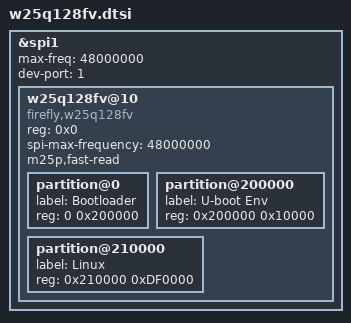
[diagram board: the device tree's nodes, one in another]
&spi1 {
	status = "okay";
	max-freq = <48000000>;
	dev-port = <1>;

	w25q128fv@10{
		status = "okay";
		#address-cells = <1>;
		#size-cells = <1>;
		compatible = "firefly,w25q128fv";
		reg = <0x0>;
		spi-max-frequency = <48000000>;
		m25p,fast-read;

		partition@0 {
			label = "Bootloader";
			reg = <0 0x200000>;
		};
		partition@200000 {
			label = "U-boot Env";
			reg = <0x200000 0x10000>;
		};
		partition@210000 {
			label = "Linux";
			reg = <0x210000 0xDF0000>;
		};
	};
};
